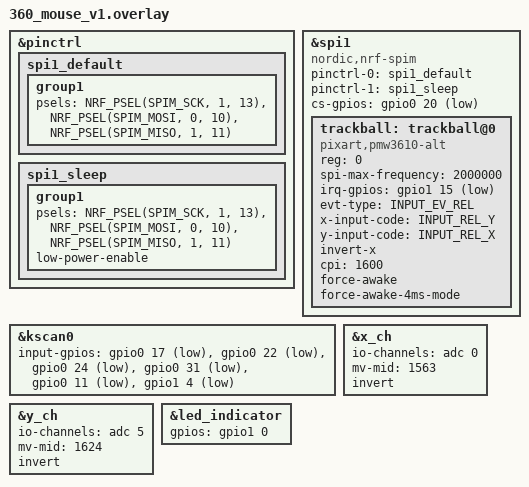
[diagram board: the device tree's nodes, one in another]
/*
 * 360 Mouse v1 - hand-wired legacy build.
 * Sensor rotated 90 deg, pots on the 3.3 V rail (no power gating).
 */

#include "360_mouse.dtsi"

&pinctrl {
    spi1_default: spi1_default {
        group1 {
            psels = <NRF_PSEL(SPIM_SCK, 1, 13)>,
                <NRF_PSEL(SPIM_MOSI, 0, 10)>,
                <NRF_PSEL(SPIM_MISO, 1, 11)>;
        };
    };
    spi1_sleep: spi1_sleep {
        group1 {
            psels = <NRF_PSEL(SPIM_SCK, 1, 13)>,
                <NRF_PSEL(SPIM_MOSI, 0, 10)>,
                <NRF_PSEL(SPIM_MISO, 1, 11)>;
            low-power-enable;
        };
    };
};

&spi1 {
    status = "okay";
    compatible = "nordic,nrf-spim";
    pinctrl-0 = <&spi1_default>;
    pinctrl-1 = <&spi1_sleep>;
    pinctrl-names = "default", "sleep";
    cs-gpios = <&gpio0 20 GPIO_ACTIVE_LOW>;

    trackball: trackball@0 {
        status = "okay";
        compatible = "pixart,pmw3610-alt";
        reg = <0>;
        spi-max-frequency = <2000000>;
        irq-gpios = <&gpio1 15 (GPIO_ACTIVE_LOW | GPIO_PULL_UP)>;
        evt-type = <INPUT_EV_REL>;
        x-input-code = <INPUT_REL_Y>;
        y-input-code = <INPUT_REL_X>;
        invert-x;
        cpi = <1600>;
        force-awake;
        force-awake-4ms-mode;
    };
};

&kscan0 {
    input-gpios =
        <&gpio0 17 (GPIO_ACTIVE_LOW | GPIO_PULL_UP)>,  /* left   */
        <&gpio0 22 (GPIO_ACTIVE_LOW | GPIO_PULL_UP)>,  /* middle */
        <&gpio0 24 (GPIO_ACTIVE_LOW | GPIO_PULL_UP)>,  /* right  */
        <&gpio0 31 (GPIO_ACTIVE_LOW | GPIO_PULL_UP)>,  /* MB4    */
        <&gpio0 11 (GPIO_ACTIVE_LOW | GPIO_PULL_UP)>,  /* MB5    */
        <&gpio1 4  (GPIO_ACTIVE_LOW | GPIO_PULL_UP)>;  /* space  */
};

&x_ch {
    io-channels = <&adc 0>;     /* P0.02 / AIN0 */
    mv-mid = <1563>;            /* sanity reference; calibrated at boot */
    invert;
};

&y_ch {
    io-channels = <&adc 5>;     /* P0.29 / AIN5 */
    mv-mid = <1624>;
    invert;
};

&led_indicator {
    gpios = <&gpio1 0 GPIO_ACTIVE_HIGH>;   /* P1.00 */
};
